AUTOSAR XML (schema 00046)
package /ComponentTypes
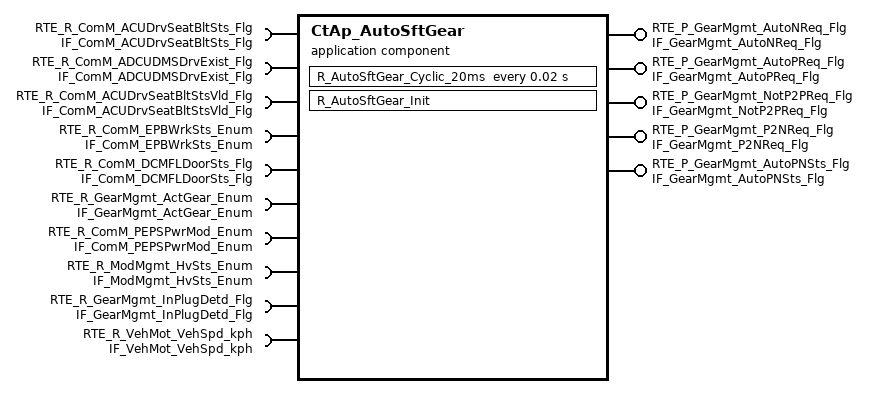
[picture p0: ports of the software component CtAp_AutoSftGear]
  application sw component type CtAp_AutoSftGear
    10 x require port:
      RTE_R_ComM_ACUDrvSeatBltSts_Flg: nonqueued-receiver-com-spec{data-element=tec_ComM_ACUDrvSeatBltSts_Flg, filter=data-filter-type=ALWAYS, init-value=0}, required-interface=IF_ComM_ACUDrvSeatBltSts_Flg
      RTE_R_ComM_ADCUDMSDrvExist_Flg: nonqueued-receiver-com-spec{data-element=tec_ComM_ADCUDMSDrvrExist_Flg, filter=data-filter-type=ALWAYS, init-value=0}, required-interface=IF_ComM_ADCUDMSDrvExist_Flg
      RTE_R_ComM_ACUDrvSeatBltStsVld_Flg: nonqueued-receiver-com-spec{data-element=tec_ComM_ACUDrvSeatBltStsVld_Flg, filter=data-filter-type=ALWAYS, init-value=0}, required-interface=IF_ComM_ACUDrvSeatBltStsVld_Flg
      RTE_R_ComM_EPBWrkSts_Enum: nonqueued-receiver-com-spec{data-element=tec_ComM_EPBWrkSts_Enum, filter=data-filter-type=ALWAYS, init-value=0}, required-interface=IF_ComM_EPBWrkSts_Enum
      RTE_R_ComM_DCMFLDoorSts_Flg: nonqueued-receiver-com-spec{data-element=tec_ComM_DCMFLDoorSts_Flg, filter=data-filter-type=ALWAYS, init-value=0}, required-interface=IF_ComM_DCMFLDoorSts_Flg
      RTE_R_GearMgmt_ActGear_Enum: nonqueued-receiver-com-spec{data-element=tec_GearMgmt_ActGear_Enum, filter=data-filter-type=ALWAYS, init-value=0}, required-interface=IF_GearMgmt_ActGear_Enum
      RTE_R_ComM_PEPSPwrMod_Enum: nonqueued-receiver-com-spec{data-element=tec_ComM_PEPSPwrMod_Enum, filter=data-filter-type=ALWAYS, init-value=0}, required-interface=IF_ComM_PEPSPwrMod_Enum
      RTE_R_ModMgmt_HvSts_Enum: nonqueued-receiver-com-spec{data-element=tec_ModMgmt_HvSts_Enum, filter=data-filter-type=ALWAYS, init-value=0}, required-interface=IF_ModMgmt_HvSts_Enum
      RTE_R_GearMgmt_InPlugDetd_Flg: nonqueued-receiver-com-spec{data-element=tec_GearMgmt_InPlugDetd_Flg, filter=data-filter-type=ALWAYS, init-value=0}, required-interface=IF_GearMgmt_InPlugDetd_Flg
      RTE_R_VehMot_VehSpd_kph: nonqueued-receiver-com-spec{data-element=tec_VehMot_VehSpd_kph, filter=data-filter-type=ALWAYS, init-value=0}, required-interface=IF_VehMot_VehSpd_kph
    5 x provide port:
      RTE_P_GearMgmt_AutoNReq_Flg: nonqueued-sender-com-spec{data-element=tec_GearMgmt_AutoNReq_Flg, init-value=0}, provided-interface=IF_GearMgmt_AutoNReq_Flg
      RTE_P_GearMgmt_AutoPReq_Flg: nonqueued-sender-com-spec{data-element=tec_GearMgmt_AutoPReq_Flg, init-value=0}, provided-interface=IF_GearMgmt_AutoPReq_Flg
      RTE_P_GearMgmt_NotP2PReq_Flg: nonqueued-sender-com-spec{data-element=tec_GearMgmt_NotP2PReq_Flg, init-value=0}, provided-interface=IF_GearMgmt_NotP2PReq_Flg
      RTE_P_GearMgmt_P2NReq_Flg: nonqueued-sender-com-spec{data-element=tec_GearMgmt_P2NReq_Flg, init-value=0}, provided-interface=IF_GearMgmt_P2NReq_Flg
      RTE_P_GearMgmt_AutoPNSts_Flg: nonqueued-sender-com-spec{data-element=tec_GearMgmt_AutoPNSts_Flg, init-value=0}, provided-interface=IF_GearMgmt_AutoPNSts_Flg
    behavior CtAp_AutoSftGear_InternalBehavior
      init event CtAp_AutoSftGear_InitEvent: start-on-event=R_AutoSftGear_Init
      timing event TMT_R_AutoSftGear_Cyclic_20ms: start-on-event=R_AutoSftGear_Cyclic_20ms, period=0.02
      runnable R_AutoSftGear_Init
      runnable R_AutoSftGear_Cyclic_20ms
        data-receive-point-by-arguments:
          10 x access:
            REC_RTE_R_ComM_ACUDrvSeatBltStsVld_Flg_tec_ComM_ACUDrvSeatBltStsVld_Flg: accessed-variable=RTE_R_ComM_ACUDrvSeatBltStsVld_Flg.tec_ComM_ACUDrvSeatBltStsVld_Flg
            REC_RTE_R_ComM_ACUDrvSeatBltSts_Flg_tec_ComM_ACUDrvSeatBltSts_Flg: accessed-variable=RTE_R_ComM_ACUDrvSeatBltSts_Flg.tec_ComM_ACUDrvSeatBltSts_Flg
            REC_RTE_R_ComM_ADCUDMSDrvExist_Flg_tec_ComM_ADCUDMSDrvrExist_Flg: accessed-variable=RTE_R_ComM_ADCUDMSDrvExist_Flg.tec_ComM_ADCUDMSDrvrExist_Flg
            REC_RTE_R_ComM_DCMFLDoorSts_Flg_tec_ComM_DCMFLDoorSts_Flg: accessed-variable=RTE_R_ComM_DCMFLDoorSts_Flg.tec_ComM_DCMFLDoorSts_Flg
            REC_RTE_R_ComM_EPBWrkSts_Enum_tec_ComM_EPBWrkSts_Enum: accessed-variable=RTE_R_ComM_EPBWrkSts_Enum.tec_ComM_EPBWrkSts_Enum
            REC_RTE_R_ComM_PEPSPwrMod_Enum_tec_ComM_PEPSPwrMod_Enum: accessed-variable=RTE_R_ComM_PEPSPwrMod_Enum.tec_ComM_PEPSPwrMod_Enum
            REC_RTE_R_GearMgmt_ActGear_Enum_tec_GearMgmt_ActGear_Enum: accessed-variable=RTE_R_GearMgmt_ActGear_Enum.tec_GearMgmt_ActGear_Enum
            REC_RTE_R_GearMgmt_InPlugDetd_Flg_tec_GearMgmt_InPlugDetd_Flg: accessed-variable=RTE_R_GearMgmt_InPlugDetd_Flg.tec_GearMgmt_InPlugDetd_Flg
            REC_RTE_R_ModMgmt_HvSts_Enum_tec_ModMgmt_HvSts_Enum: accessed-variable=RTE_R_ModMgmt_HvSts_Enum.tec_ModMgmt_HvSts_Enum
            REC_RTE_R_VehMot_VehSpd_kph_tec_VehMot_VehSpd_kph: accessed-variable=RTE_R_VehMot_VehSpd_kph.tec_VehMot_VehSpd_kph
        data-send-points:
          5 x access:
            SEND_RTE_P_GearMgmt_AutoNReq_Flg_tec_GearMgmt_AutoNReq_Flg: accessed-variable=RTE_P_GearMgmt_AutoNReq_Flg.tec_GearMgmt_AutoNReq_Flg
            SEND_RTE_P_GearMgmt_AutoPNSts_Flg_tec_GearMgmt_AutoPNSts_Flg: accessed-variable=RTE_P_GearMgmt_AutoPNSts_Flg.tec_GearMgmt_AutoPNSts_Flg
            SEND_RTE_P_GearMgmt_AutoPReq_Flg_tec_GearMgmt_AutoPReq_Flg: accessed-variable=RTE_P_GearMgmt_AutoPReq_Flg.tec_GearMgmt_AutoPReq_Flg
            SEND_RTE_P_GearMgmt_NotP2PReq_Flg_tec_GearMgmt_NotP2PReq_Flg: accessed-variable=RTE_P_GearMgmt_NotP2PReq_Flg.tec_GearMgmt_NotP2PReq_Flg
            SEND_RTE_P_GearMgmt_P2NReq_Flg_tec_GearMgmt_P2NReq_Flg: accessed-variable=RTE_P_GearMgmt_P2NReq_Flg.tec_GearMgmt_P2NReq_Flg
  swc implementation CtAp_AutoSftGear_Implementation: behavior=CtAp_AutoSftGear_InternalBehavior
    code-descriptors:
      code Default: artifact-descriptors=autosar-engineering-object=category=SWOBJ
